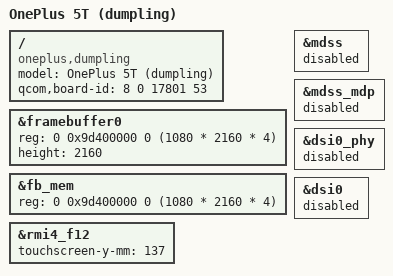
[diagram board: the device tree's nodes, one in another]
// SPDX-License-Identifier: GPL-2.0
/* Copyright (c) 2016, The Linux Foundation. All rights reserved. */

/dts-v1/;

#include "msm8998-cheeseburger.dtsi"

/ {
	model = "OnePlus 5T (dumpling)";
	compatible = "oneplus,dumpling", "qcom,msm8998";

	qcom,board-id = <8 0 17801 53>;
};

// Update the screen heights from 1920 to 2160 on the 5T
&framebuffer0 {
	reg = <0 0x9d400000 0 (1080 * 2160 * 4)>;
	height = <2160>;
};

&fb_mem {
	reg = <0 0x9d400000 0 (1080 * 2160 * 4)>;
};

// Adjust digitizer area height to match the 5T's taller panel
&rmi4_f12 {
	touchscreen-y-mm = <137>;
};

// Disable all display panel related nodes until there is a proper driver to
// test for the Samsung S6E3FC1 found on the 5T
&mdss {
	status = "disabled";
};

&mdss_mdp {
	status = "disabled";
};

&dsi0_phy {
	status = "disabled";
};

&dsi0 {
	status = "disabled";
};
